# OCP2SCP register map
Vendor: Texas Instruments
Peripheral module from a debugger description file (folder omap4430).
Registers are 32-bit, read-only, no defined reset value unless marked. A register's access mark holds for its fields unless they carry their own. Offsets are as the file gives them; lines under a group give offsets from that group; [hi:lo] are bit positions; {n}, {i} and the like mark numbered series; 'fields as' and 'values as' point back to an identical list; <NAME> marks a mode.

## OCP2SCP
0x00 OCP2SCP_REVISION — IP revision identifier
  [31:0] REVISION — IP revision number
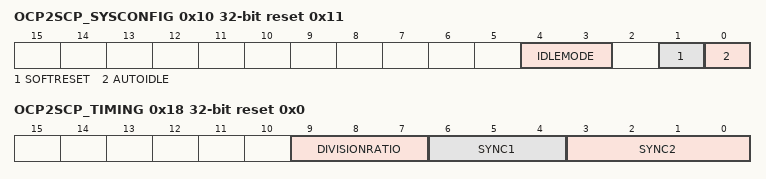
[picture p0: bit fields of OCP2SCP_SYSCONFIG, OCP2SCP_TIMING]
0x10 OCP2SCP_SYSCONFIG access per field reset 0x11 — System configuration register
  [4:3] IDLEMODE rw — Module power management control
    0=Force-idle mode. An idle request is acknowledged unconditionally.; 1=No-idle mode. An idle request is never acknowledged.; 2=Smart-idle mode. The acknowledgment to an idle request is given based on the internal activity.
  [1] SOFTRESET rw — Software reset. Set this bit to 1 to trigger a module reset. During reads, it always returns 0.
    0=Normal mode; 1=The module is reset
  [0] AUTOIDLE rw — OCP clock-gating control
    0=Internal interface OCP clock is free-running; 1=Automatic internal OCP clock gating, based on the OCP interface activity
0x14 OCP2SCP_SYSSTATUS reset 0x1 — System status register
  [0] RESETDONE — 0: Internal reset is on-going.
    1=Reset is complete
0x18 OCP2SCP_TIMING access not given reset 0x0 (reset mask 0xFFFFFFF0) — Timing configuration register
  [9:7] DIVISIONRATIO rw — Division ratio of the SCP clock in relation to the OCP input clock. When the value 0x0 is programmed, and the transaction to be made is a valid transaction on the SCP interface, the value of DIVISIONRATIO is set to 0x7 by hardware to avoid a block on the OCP interface.CAUTION:To ensure correct operation, DIVISIONRATIO must not be modified. See also the SYNC2 description. .
  [6:4] SYNC1 rw — Number of SCP clock cycles defining SYNC1 delay
  [3:0] SYNC2 — Number of SCP clock cycles defining the SYNC2 delay. When the value 0x0 is programmed, and the transaction to be made is a valid transaction on the SCP interface, SYNC2 is set to the minimum allowed value 0x1 to avoid a block on the OCP interface.CAUTION:To ensure correct operation, the value of SYNC2 must be set to 0x6 or more. RW 0x1 .
